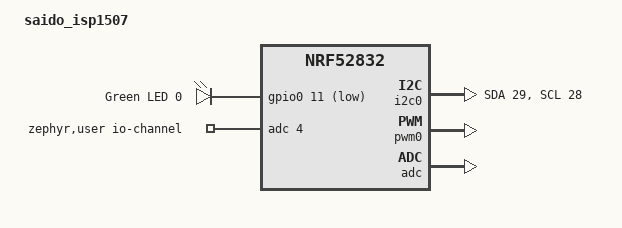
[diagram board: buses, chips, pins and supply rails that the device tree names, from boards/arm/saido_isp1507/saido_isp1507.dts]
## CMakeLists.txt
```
# SPDX-License-Identifier: Apache-2.0

cmake_minimum_required(VERSION 3.20.0)
find_package(Zephyr REQUIRED HINTS $ENV{ZEPHYR_BASE})
project(sensor)

target_sources(app
    PRIVATE
        src/main.c src/sht3x.c src/qmp6988.c src/sgp30.c
        src/battery.c
        src/app_bt.c
    )
```

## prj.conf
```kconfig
CONFIG_GPIO=y
CONFIG_LOG=y
CONFIG_LOG_DEFAULT_LEVEL=4
CONFIG_RTT_CONSOLE=y
# CONFIG_CBPRINTF_FP_SUPPORT=y
CONFIG_I2C=y
CONFIG_ADC=y
CONFIG_NEWLIB_LIBC=y

CONFIG_BT=y
CONFIG_BT_PERIPHERAL=y
CONFIG_BT_DEVICE_NAME="nrf52_sensor"
```

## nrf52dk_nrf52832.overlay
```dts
// To get started, press Ctrl+Space to bring up the completion menu and view the available nodes.
// For more help, browse the DeviceTree documentation at https: //docs.zephyrproject.org/latest/guides/dts/index.html
/ {
    model = "saido isp1507";
    compatible = "nordic,nrf52-dk-nrf52832";

    chosen {
        zephyr,console = &uart0;
        zephyr,shell-uart = &uart0;
        zephyr,uart-mcumgr = &uart0;
        zephyr,bt-mon-uart = &uart0;
        zephyr,bt-c2h-uart = &uart0;
        zephyr,sram = &sram0;
        zephyr,flash = &flash0;
        zephyr,code-partition = &slot0_partition;
    };

    leds {
        compatible = "gpio-leds";
        led0: led_0 {
            gpios = <&gpio0 11 GPIO_ACTIVE_LOW>;
            label = "on board led";
        };
        led1: led_1 {
            status = "disabled";
        };
        led2: led_2 {
            status = "disabled";
        };
        led3: led_3 {
            status = "disabled";
        };
    };

    pwmleds {
        compatible = "pwm-leds";
        pwm_led0: pwm_led_0 {
            pwms = <&pwm0 11>;
        };
    };

    buttons {
        status = "disabled";
    };

    arduino_header: connector {
        status = "disabled";
    };

    arduino_adc: analog-connector {
        status = "disabled";
    };

    /* These aliases are provided for compatibility with samples */
    aliases {
        led0 = &led0;
        led1 = &led1;
        led2 = &led2;
        led3 = &led3;
        pwm-led0 = &pwm_led0;
        sw0 = &button0;
        sw1 = &button1;
        sw2 = &button2;
        sw3 = &button3;
        bootloader-led0 = &led0;
    };
};

&adc {
    status = "disabled";
};

&gpiote {
    status = "okay";
};

&gpio0 {
    status = "okay";
};

arduino_serial: &uart0 {
    status = "disabled";
};

arduino_i2c: &i2c0 {
    compatible = "nordic,nrf-twi";
    status = "okay";
    sda-pin = <29>;
    scl-pin = <28>;
};

&i2c1 {
    compatible = "nordic,nrf-twi";
    /* Cannot be used together with spi1. */
    status = "disabled";
};

&pwm0 {
    status = "okay";
    ch0-pin = <17>;
    ch0-inverted;
};

&spi0 {
    compatible = "nordic,nrf-spi";
    /* Cannot be used together with i2c0. */
    status = "disabled";
};

&spi1 {
    compatible = "nordic,nrf-spi";
    status = "disabled";
};

arduino_spi: &spi2 {
    compatible = "nordic,nrf-spi";
    status = "disabled";
};

&flash0 {

    partitions {
        compatible = "fixed-partitions";
        #address-cells = <1>;
        #size-cells = <1>;

        boot_partition: partition@0 {
            label = "mcuboot";
            reg = <0x00000000 0xc000>;
        };
        slot0_partition: partition@c000 {
            label = "image-0";
            reg = <0x0000C000 0x32000>;
        };
        slot1_partition: partition@3e000 {
            label = "image-1";
            reg = <0x0003E000 0x32000>;
        };
        scratch_partition: partition@70000 {
            label = "image-scratch";
            reg = <0x00070000 0xa000>;
        };
        storage_partition: partition@7a000 {
            label = "storage";
            reg = <0x0007a000 0x00006000>;
        };
    };
};
```

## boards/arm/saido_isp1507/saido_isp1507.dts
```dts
// Copyright (c) 2022 Nordic Semiconductor ASA
// SPDX-License-Identifier: Apache-2.0

/dts-v1/;
#include <nordic/nrf52832_ciaa.dtsi>

/ {
	model = "saido_isp1507";
	compatible = "h-saido,saido-isp1507";

	chosen {
		zephyr,sram = &sram0;
		zephyr,flash = &flash0;
		zephyr,code-partition = &slot0_partition;
	};

	leds {
		compatible = "gpio-leds";
		led0: led_0 {
			gpios = <&gpio0 11 GPIO_ACTIVE_LOW>;
			label = "Green LED 0";
		};
	};

	// FIXME: Error on NCS v2.0.0 (This can build with NCS v1.9.1 or lower)
	// pwmleds {
	// 	compatible = "pwm-leds";
	// 	pwm_led0: pwm_led_0 {
	// 		pwms = <&pwm0 11>;
	// 	};
	// };


	/* These aliases are provided for compatibility with samples */
	aliases {
		led0 = &led0;
		// pwm-led0 = &pwm_led0;
		bootloader-led0 = &led0;
	};

	zephyr,user {
		io-channels = <&adc 4>;
	 };
};

&gpio0 {
	status = "okay";
};

i2c: &i2c0 {
	compatible = "nordic,nrf-twi";
	status = "okay";
	sda-pin = <29>;
	scl-pin = <28>;
};

&pwm0 {
	status = "okay";
	ch0-pin = <11>;
	ch0-inverted;
};

&adc {
	status = "okay";
};

&flash0 {
	partitions {
		compatible = "fixed-partitions";
		#address-cells = <1>;
		#size-cells = <1>;

		boot_partition: partition@0 {
			label = "mcuboot";
			reg = <0x0 0xc000>;
		};
		slot0_partition: partition@c000 {
			label = "image-0";
			reg = <0xc000 0x32000>;
		};
		slot1_partition: partition@3e000 {
			label = "image-1";
			reg = <0x3e000 0x32000>;
		};
		scratch_partition: partition@70000 {
			label = "image-scratch";
			reg = <0x70000 0xa000>;
		};
		storage_partition: partition@7a000 {
			label = "storage";
			reg = <0x7a000 0x6000>;
		};
	};
};
```

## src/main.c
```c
/*
 * Copyright (c) 2016 Intel Corporation
 *
 * SPDX-License-Identifier: Apache-2.0
 */

#include <stdio.h>

#include <device.h>
#include <devicetree.h>
#include <drivers/gpio.h>
#include <drivers/i2c.h>
#include <kernel.h>
#include <zephyr.h>

#include <logging/log.h>
LOG_MODULE_REGISTER(sensor);

#include "battery.h"
#include "qmp6988.h"
#include "sgp30.h"
#include "sht3x.h"

#include "app_bt.h"

/* 1000 msec = 1 sec */
#define SLEEP_TIME_MS 5000

// NOTE: SGP30 is very high comsumption (about 50 mA), so disable it
#define CONFIG_SGP30

struct sensors {
    const struct device *i2c_dev;
    sht3x_sensor_t      *sht3x;
    qmp6988_sensor_t    *qmp6988;
#ifdef CONFIG_SGP30
    sgp30_sensor_t *sgp30;
#endif
    float temperature;
    float humidity;
    float pressure;
    float temperature_p;
};

typedef struct {
    int   battery_mV;
    float temperature;
    float humidity;
    float pressure;
#ifdef CONFIG_SGP30
    uint16_t co2;
    uint16_t tvoc;
#endif
} send_data_t;

static struct sensors env_sensors = {
    .i2c_dev = DEVICE_DT_GET(DT_NODELABEL(i2c0)),
    .sht3x   = NULL,
    .qmp6988 = NULL,
#ifdef CONFIG_SGP30
    .sgp30 = NULL,
#endif
};

static struct gpio_dt_spec led0_spec = GPIO_DT_SPEC_GET(DT_NODELABEL(led0), gpios);

static send_data_t send_data = {
    .battery_mV  = 0,
    .temperature = 0,
    .humidity    = 0,
    .pressure    = 0,
#ifdef CONFIG_SGP30
    .co2  = 0,
    .tvoc = 0,
#endif
};

static bool init_i2c_sensors(struct sensors *env_sensors);
static void get_i2c_sensors_values(struct sensors *env_sensors);
static void app_work_handler(struct k_work *work);
static void app_timer_handler(struct k_timer *dummy);

K_WORK_DEFINE(app_work, app_work_handler);
K_TIMER_DEFINE(app_timer, app_timer_handler, NULL);

static void app_work_handler(struct k_work *work)
{
    gpio_pin_set_dt(&led0_spec, 0);

    battery_measure_enable(true);
    int batt_mV = battery_sample();
    if (batt_mV < 0) {
        LOG_WRN("Failed to read battery voltage: %d\n", batt_mV);
    } else {
        send_data.battery_mV = batt_mV;
    }
    battery_measure_enable(false);

    get_i2c_sensors_values(&env_sensors);
#ifdef CONFIG_SGP30
    LOG_INF(
        "%d C %d %% %4d hPa(t=%2d) %d ppm CO2 %d ppm TVOC %d mV", (int)env_sensors.temperature,
        (int)env_sensors.humidity, (int)env_sensors.pressure, (int)env_sensors.temperature_p, env_sensors.sgp30->CO2,
        env_sensors.sgp30->TVOC, batt_mV
    );
#else
    LOG_INF(
        "%d C %d %% %4d hPa(t=%2d) %d mV", (int)env_sensors.temperature, (int)env_sensors.humidity,
        (int)env_sensors.pressure, (int)env_sensors.temperature_p, batt_mV
    );
#endif

    send_data.temperature = env_sensors.temperature;
    send_data.humidity    = env_sensors.humidity;
    send_data.pressure    = env_sensors.pressure;
#ifdef CONFIG_SGP30
    send_data.co2 = env_sensors.sgp30->CO2;
    send_data.tvoc = env_sensors.sgp30->TVOC;
#endif
    bt_app_send_data(&send_data, sizeof(send_data_t));

    gpio_pin_set_dt(&led0_spec, 1);
}

static void app_timer_handler(struct k_timer *dummy)
{
    k_work_submit(&app_work);
}

static void connected(struct bt_conn *conn, uint8_t err)
{
    if (err) {
        printk("Connection failed (err %u)\n", err);
        return;
    }

    printk("Connected\n");
}

static void disconnected(struct bt_conn *conn, uint8_t reason)
{
    printk("Disconnected (reason %u)\n", reason);
}

BT_CONN_CB_DEFINE(conn_callbacks) = {
    .connected    = connected,
    .disconnected = disconnected,
};

static int app_bt_cb(void *data)
{
    // Note: The maximum data size is defined by APP_BT_MAX_ATTR_LEN.
    if (APP_BT_MAX_ATTR_LEN < sizeof(send_data_t)) {
        LOG_ERR("app_bt_cb(): Too large data size");
        return -EINVAL;
    }
    memcpy(data, &send_data, sizeof(send_data_t));
    return sizeof(send_data_t);
}

static struct bt_app_cb app_callbacks = {
    .app_bt_cb = app_bt_cb,
};

static bool init_i2c_sensors(struct sensors *env_sensors)
{
    env_sensors->sht3x = sht3x_init_sensor(env_sensors->i2c_dev, SHT3x_ADDR_1);
    if (env_sensors->sht3x == NULL) {
        LOG_ERR("Cannot init sht3x sensor");
        return false;
    }

    // Wait until first measurement is ready (constant time of at least 30 ms
    // or the duration returned from *sht3x_get_measurement_duration*).
    k_msleep(sht3x_get_measurement_duration(sht3x_high));

    env_sensors->qmp6988 = qmp6988_init_sensor(env_sensors->i2c_dev, QMP6988_SLAVE_ADDRESS_L);
    if (env_sensors->qmp6988 == NULL) {
        LOG_ERR("Cannot init qmp6988 sensor");
        return false;
    }

#ifdef CONFIG_SGP30
    env_sensors->sgp30 = sgp30_init_sensor(env_sensors->i2c_dev, SGP30_I2C_DEFAULT_ADDRESS);
    if (env_sensors->sgp30 == NULL) {
        LOG_ERR("Cannot init sgp30 sensor");
        return false;
    }
    sgp30_initAirQuality(env_sensors->sgp30);
    k_msleep(INIT_AIR_QUALITY_DURATION_MS);
#endif

    return true;
}

static void get_i2c_sensors_values(struct sensors *env_sensors)
{
    int ret;
    ret = sht3x_measure(env_sensors->sht3x, &env_sensors->temperature, &env_sensors->humidity);
    qmp6988_calcPressure(env_sensors->qmp6988, &env_sensors->pressure, &env_sensors->temperature_p);
#ifdef CONFIG_SGP30
    sgp30_measureAirQuality(env_sensors->sgp30);
    if (ret) {
        sgp30_setCompensation(env_sensors->sgp30, env_sensors->humidity, env_sensors->temperature);
    }
#endif
}

void main(void)
{
    LOG_MODULE_DECLARE(sensor);
    int ret;

    ret = gpio_pin_configure_dt(&led0_spec, GPIO_OUTPUT_ACTIVE);
    if (ret < 0) {
        LOG_ERR("Cannot configure LED pin [%d]", ret);
        return;
    }

    ret = init_i2c_sensors(&env_sensors);
    if (!ret) {
        LOG_ERR("Cannot init i2c sensors [%d]", ret);
        return;
    }

    ret = bt_app_init(&app_callbacks);
    if (ret) {
        LOG_ERR("Failed to init bt [%d]", ret);
        return;
    }

    ret = bt_app_advertise_start();
    if (ret) {
        LOG_ERR("Failed to start advertising [%d]", ret);
        return;
    }

    /* start periodic timer that expires once every 10 seconds */
    k_timer_start(&app_timer, K_SECONDS(1), K_MSEC(SLEEP_TIME_MS));

    // do nothing
}
```

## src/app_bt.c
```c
#include <errno.h>
#include <stddef.h>
#include <string.h>
#include <sys/byteorder.h>
#include <sys/printk.h>
#include <zephyr.h>
#include <zephyr/types.h>

#include <bluetooth/bluetooth.h>
#include <bluetooth/conn.h>
#include <bluetooth/gatt.h>
#include <bluetooth/hci.h>
#include <bluetooth/uuid.h>

#include <logging/log.h>

#include "app_bt.h"

LOG_MODULE_REGISTER(app_bt, CONFIG_LOG_DEFAULT_LEVEL);

static bool             notify_enabled;
static char             char_value[APP_BT_MAX_ATTR_LEN];
static struct bt_app_cb app_cb;

static void app_ccc_cfg_changed(const struct bt_gatt_attr *attr, uint16_t value)
{
    notify_enabled = (value == BT_GATT_CCC_NOTIFY);
}

static ssize_t read_function(
    struct bt_conn *conn, const struct bt_gatt_attr *attr, void *buf, uint16_t len, uint16_t offset
)
{
    LOG_DBG("Attribute read, handle: %u, conn: %p", attr->handle, (void *)conn);

    if (app_cb.app_bt_cb) {
        int data_len = app_cb.app_bt_cb(attr->user_data);
        if (data_len < 0) {
            return data_len;
        }

        return bt_gatt_attr_read(conn, attr, buf, len, offset, attr->user_data, data_len);
    }

    return 0;
}

BT_GATT_SERVICE_DEFINE(
    app_svc, BT_GATT_PRIMARY_SERVICE(APP_BT_UUID_BASE),
    BT_GATT_CHARACTERISTIC(
        APP_BT_UUID_CHAR, BT_GATT_CHRC_READ | BT_GATT_CHRC_NOTIFY, BT_GATT_PERM_READ, read_function, NULL, char_value
    ),
    BT_GATT_CCC(app_ccc_cfg_changed, BT_GATT_PERM_READ | BT_GATT_PERM_WRITE),
);

int bt_app_init(struct bt_app_cb *callbacks)
{
    if (callbacks) {
        app_cb.app_bt_cb = callbacks->app_bt_cb;
    }

    return bt_enable(NULL);
}

int bt_app_send_data(void *data, int len)
{
    if (!notify_enabled) {
        return -EACCES;
    }

    return bt_gatt_notify(NULL, &app_svc.attrs[2], data, (uint16_t)len);
}

int bt_app_advertise_start(void)
{
    const struct bt_data ad[] = {
        BT_DATA_BYTES(BT_DATA_FLAGS, (BT_LE_AD_GENERAL | BT_LE_AD_NO_BREDR)),
        BT_DATA(BT_DATA_NAME_COMPLETE, DEVICE_NAME, DEVICE_NAME_LEN),
    };

    const struct bt_data sd[] = {
        BT_DATA_BYTES(BT_DATA_UUID128_ALL, APP_BT_UUID_BASE_VAL),
    };

    return bt_le_adv_start(BT_LE_ADV_CONN, ad, ARRAY_SIZE(ad), sd, ARRAY_SIZE(sd));
}
```

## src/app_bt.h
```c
#ifndef BT_APP_H_
#define BT_APP_H_

#include <bluetooth/bluetooth.h>
#include <bluetooth/conn.h>
#include <bluetooth/gatt.h>
#include <bluetooth/hci.h>
#include <bluetooth/uuid.h>

#define DEVICE_NAME     CONFIG_BT_DEVICE_NAME
#define DEVICE_NAME_LEN (sizeof(DEVICE_NAME) - 1)
// random number
#define APP_BT_UUID_BASE_VAL BT_UUID_128_ENCODE(0xc7839aa8, 0x1903, 0x40b5, 0xa8f0, 0x426e09ffb390)
#define APP_BT_UUID_CHAR_VAL BT_UUID_128_ENCODE(0xc7839aa9, 0x1903, 0x40b5, 0xa8f0, 0x426e09ffb390)

#define APP_BT_UUID_BASE BT_UUID_DECLARE_128(APP_BT_UUID_BASE_VAL)
#define APP_BT_UUID_CHAR BT_UUID_DECLARE_128(APP_BT_UUID_CHAR_VAL)

#define APP_BT_MAX_ATTR_LEN 64

typedef int (*app_bt_cb_t)(void *data);

struct bt_app_cb {
    app_bt_cb_t app_bt_cb;
};

/** @brief Initialize the app_bt Service.
 *
 * @param[in] callbacks Struct containing pointers to callback functions
 *			used by the service. This pointer can be NULL
 *			if no callback functions are defined.
 *
 * @retval 0 If the operation was successful.
 *           Otherwise, a (negative) error code is returned.
 */
int bt_app_init(struct bt_app_cb *callbacks);

/** @brief Send data (notify).
 *
 * If the notify is not enabled, the data will be discarded.
 *
 * @param[in] data notify data. Able to input any data.
 * @param[in] len length of notify data.
 *
 * @retval 0 If the operation was successful.
 *           Otherwise, a (negative) error code is returned.
 */
int bt_app_send_data(void *data, int len);

/** @brief Start advertising.
 *
 * @retval 0 If the operation was successful.
 *           Otherwise, a (negative) error code is returned.
 */
int bt_app_advertise_start(void);

#endif
```

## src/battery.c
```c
/*
 * Copyright (c) 2018-2019 Peter Bigot Consulting, LLC
 * Copyright (c) 2019-2020 Nordic Semiconductor ASA
 *
 * SPDX-License-Identifier: Apache-2.0
 */

#include <math.h>
#include <stdio.h>
#include <stdlib.h>

#include <drivers/adc.h>
#include <drivers/gpio.h>
#include <drivers/sensor.h>
#include <init.h>
#include <logging/log.h>
#include <zephyr.h>

#include "battery.h"

LOG_MODULE_REGISTER(BATTERY, CONFIG_ADC_LOG_LEVEL);

#define VBATT       DT_PATH(vbatt)
#define ZEPHYR_USER DT_PATH(zephyr_user)

#ifdef CONFIG_BOARD_THINGY52_NRF52832
/* This board uses a divider that reduces max voltage to
 * reference voltage (600 mV).
 */
#define BATTERY_ADC_GAIN ADC_GAIN_1
#else
/* Other boards may use dividers that only reduce battery voltage to
 * the maximum supported by the hardware (3.6 V)
 */
#define BATTERY_ADC_GAIN ADC_GAIN_1_6
#endif

struct io_channel_config {
    uint8_t channel;
};

struct gpio_channel_config {
    const char *label;
    uint8_t     pin;
    uint8_t     flags;
};

struct divider_config {
    struct io_channel_config   io_channel;
    struct gpio_channel_config power_gpios;
    /* output_ohm is used as a flag value: if it is nonzero then
     * the battery is measured through a voltage divider;
     * otherwise it is assumed to be directly connected to Vdd.
     */
    uint32_t output_ohm;
    uint32_t full_ohm;
};

static const struct divider_config divider_config = {
#if DT_NODE_HAS_STATUS(VBATT, okay)
    .io_channel =
        {
            DT_IO_CHANNELS_INPUT(VBATT),
        },
#if DT_NODE_HAS_PROP(VBATT, power_gpios)
    .power_gpios =
        {
            DT_GPIO_LABEL(VBATT, power_gpios),
            DT_GPIO_PIN(VBATT, power_gpios),
            DT_GPIO_FLAGS(VBATT, power_gpios),
        },
#endif
    .output_ohm = DT_PROP(VBATT, output_ohms),
    .full_ohm   = DT_PROP(VBATT, full_ohms),
#else  /* /vbatt exists */
    .io_channel =
        {
            DT_IO_CHANNELS_INPUT(ZEPHYR_USER),
        },
#endif /* /vbatt exists */
};

struct divider_data {
    const struct device   *adc;
    const struct device   *gpio;
    struct adc_channel_cfg adc_cfg;
    struct adc_sequence    adc_seq;
    int16_t                raw;
};
static struct divider_data divider_data = {
#if DT_NODE_HAS_STATUS(VBATT, okay)
    .adc = DEVICE_DT_GET(DT_IO_CHANNELS_CTLR(VBATT)),
#else
    .adc = DEVICE_DT_GET(DT_IO_CHANNELS_CTLR(ZEPHYR_USER)),
#endif
};

static int divider_setup(void)
{
    const struct divider_config      *cfg  = &divider_config;
    const struct io_channel_config   *iocp = &cfg->io_channel;
    const struct gpio_channel_config *gcp  = &cfg->power_gpios;
    struct divider_data              *ddp  = &divider_data;
    struct adc_sequence              *asp  = &ddp->adc_seq;
    struct adc_channel_cfg           *accp = &ddp->adc_cfg;
    int                               rc;

    if (!device_is_ready(ddp->adc)) {
        LOG_ERR("ADC device is not ready %s", ddp->adc->name);
        return -ENOENT;
    }

    if (gcp->label) {
        ddp->gpio = device_get_binding(gcp->label);
        if (ddp->gpio == NULL) {
            LOG_ERR("Failed to get GPIO %s", gcp->label);
            return -ENOENT;
        }
        rc = gpio_pin_configure(ddp->gpio, gcp->pin, GPIO_OUTPUT_INACTIVE | gcp->flags);
        if (rc != 0) {
            LOG_ERR("Failed to control feed %s.%u: %d", gcp->label, gcp->pin, rc);
            return rc;
        }
    }

    *asp = (struct adc_sequence){
        .channels     = BIT(0),
        .buffer       = &ddp->raw,
        .buffer_size  = sizeof(ddp->raw),
        .oversampling = 4,
        .calibrate    = true,
    };

#ifdef CONFIG_ADC_NRFX_SAADC
    *accp = (struct adc_channel_cfg){
        .gain             = BATTERY_ADC_GAIN,
        .reference        = ADC_REF_INTERNAL,
        .acquisition_time = ADC_ACQ_TIME(ADC_ACQ_TIME_MICROSECONDS, 40),
    };

    if (cfg->output_ohm != 0) {
        accp->input_positive = SAADC_CH_PSELP_PSELP_AnalogInput0 + iocp->channel;
    } else {
        accp->input_positive = SAADC_CH_PSELP_PSELP_VDD;
    }

    asp->resolution = 14;
#else /* CONFIG_ADC_var */
#error Unsupported ADC
#endif /* CONFIG_ADC_var */

    rc = adc_channel_setup(ddp->adc, accp);
    // LOG_INF("Setup AIN%u got %d", iocp->channel, rc);

    return rc;
}

static bool battery_ok;

static int battery_setup(const struct device *arg)
{
    int rc = divider_setup();

    battery_ok = (rc == 0);
    // LOG_INF("Battery setup: %d %d", rc, battery_ok);
    return rc;
}

SYS_INIT(battery_setup, APPLICATION, CONFIG_APPLICATION_INIT_PRIORITY);

int battery_measure_enable(bool enable)
{
    int rc = -ENOENT;

    if (battery_ok) {
        const struct divider_data        *ddp = &divider_data;
        const struct gpio_channel_config *gcp = &divider_config.power_gpios;

        rc = 0;
        if (ddp->gpio) {
            rc = gpio_pin_set(ddp->gpio, gcp->pin, enable);
        }
    }
    return rc;
}

int battery_sample(void)
{
    int rc = -ENOENT;

    if (battery_ok) {
        struct divider_data         *ddp = &divider_data;
        const struct divider_config *dcp = &divider_config;
        struct adc_sequence         *sp  = &ddp->adc_seq;

        rc            = adc_read(ddp->adc, sp);
        sp->calibrate = false;
        if (rc == 0) {
            int32_t val = ddp->raw;

            adc_raw_to_millivolts(adc_ref_internal(ddp->adc), ddp->adc_cfg.gain, sp->resolution, &val);

            if (dcp->output_ohm != 0) {
                rc = val * (uint64_t)dcp->full_ohm / dcp->output_ohm;
                // LOG_INF("raw %u ~ %u mV => %d mV\n",
                // 	ddp->raw, val, rc);
            } else {
                rc = val;
                // LOG_INF("raw %u ~ %u mV\n", ddp->raw, val);
            }
        }
    }

    return rc;
}

unsigned int battery_level_pptt(unsigned int batt_mV, const struct battery_level_point *curve)
{
    const struct battery_level_point *pb = curve;

    if (batt_mV >= pb->lvl_mV) {
        /* Measured voltage above highest point, cap at maximum. */
        return pb->lvl_pptt;
    }
    /* Go down to the last point at or below the measured voltage. */
    while ((pb->lvl_pptt > 0) && (batt_mV < pb->lvl_mV)) {
        ++pb;
    }
    if (batt_mV < pb->lvl_mV) {
        /* Below lowest point, cap at minimum */
        return pb->lvl_pptt;
    }

    /* Linear interpolation between below and above points. */
    const struct battery_level_point *pa = pb - 1;

    return pb->lvl_pptt + ((pa->lvl_pptt - pb->lvl_pptt) * (batt_mV - pb->lvl_mV) / (pa->lvl_mV - pb->lvl_mV));
}
```

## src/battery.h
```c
/*
 * Copyright (c) 2018-2019 Peter Bigot Consulting, LLC
 *
 * SPDX-License-Identifier: Apache-2.0
 */

#ifndef APPLICATION_BATTERY_H_
#define APPLICATION_BATTERY_H_

/** Enable or disable measurement of the battery voltage.
 *
 * @param enable true to enable, false to disable
 *
 * @return zero on success, or a negative error code.
 */
int battery_measure_enable(bool enable);

/** Measure the battery voltage.
 *
 * @return the battery voltage in millivolts, or a negative error
 * code.
 */
int battery_sample(void);

/** A point in a battery discharge curve sequence.
 *
 * A discharge curve is defined as a sequence of these points, where
 * the first point has #lvl_pptt set to 10000 and the last point has
 * #lvl_pptt set to zero.  Both #lvl_pptt and #lvl_mV should be
 * monotonic decreasing within the sequence.
 */
struct battery_level_point {
    /** Remaining life at #lvl_mV. */
    uint16_t lvl_pptt;

    /** Battery voltage at #lvl_pptt remaining life. */
    uint16_t lvl_mV;
};

/** Calculate the estimated battery level based on a measured voltage.
 *
 * @param batt_mV a measured battery voltage level.
 *
 * @param curve the discharge curve for the type of battery installed
 * on the system.
 *
 * @return the estimated remaining capacity in parts per ten
 * thousand.
 */
unsigned int battery_level_pptt(unsigned int batt_mV, const struct battery_level_point *curve);

#endif /* APPLICATION_BATTERY_H_ */
```

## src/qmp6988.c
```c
// https://github.com/m5stack/UNIT_ENV
//
// MIT License
//
// Copyright (c) 2021 M5Stack
//
// Permission is hereby granted, free of charge, to any person obtaining a copy
// of this software and associated documentation files (the "Software"), to deal
// in the Software without restriction, including without limitation the rights
// to use, copy, modify, merge, publish, distribute, sublicense, and/or sell
// copies of the Software, and to permit persons to whom the Software is
// furnished to do so, subject to the following conditions:
//
// The above copyright notice and this permission notice shall be included in all
// copies or substantial portions of the Software.
//
// THE SOFTWARE IS PROVIDED "AS IS", WITHOUT WARRANTY OF ANY KIND, EXPRESS OR
// IMPLIED, INCLUDING BUT NOT LIMITED TO THE WARRANTIES OF MERCHANTABILITY,
// FITNESS FOR A PARTICULAR PURPOSE AND NONINFRINGEMENT. IN NO EVENT SHALL THE
// AUTHORS OR COPYRIGHT HOLDERS BE LIABLE FOR ANY CLAIM, DAMAGES OR OTHER
// LIABILITY, WHETHER IN AN ACTION OF CONTRACT, TORT OR OTHERWISE, ARISING FROM,
// OUT OF OR IN CONNECTION WITH THE SOFTWARE OR THE USE OR OTHER DEALINGS IN THE
// SOFTWARE.

#include <stdlib.h>
#include <string.h>

#include <drivers/i2c.h>

#include "qmp6988.h"

static uint8_t qmp6988_deviceCheck(qmp6988_sensor_t *dev);
static bool    qmp6988_softwareReset(qmp6988_sensor_t *dev);
static int     qmp6988_getCalibrationData(qmp6988_sensor_t *dev);
static int16_t qmp6988_convTx02e(qmp6988_ik_data_t *ik, int32_t dt);
static int32_t qmp6988_getPressure02e(qmp6988_ik_data_t *ik, int32_t dp, int16_t tx);
static bool    qmp6988_read_data(qmp6988_sensor_t *dev, uint8_t reg_addr, uint8_t *data, uint32_t len);
static bool    qmp6988_write_reg(qmp6988_sensor_t *dev, uint8_t reg_addr, uint8_t data);

static qmp6988_sensor_t g_dev; // mallocできないのでここに宣言

qmp6988_sensor_t *qmp6988_init_sensor(const struct device *i2c_dev, uint8_t addr)
{
    qmp6988_sensor_t *dev;

    // if ((dev = malloc(sizeof(qmp6988_sensor_t))) == NULL)
    //     return NULL;
    dev = &g_dev;

    // inititalize sensor data structure
    dev->bus  = i2c_dev;
    dev->addr = addr;

    uint8_t ret = qmp6988_deviceCheck(dev);
    if (ret == 0) {
        // free(dev);
        return NULL;
    }

    qmp6988_softwareReset(dev);
    qmp6988_getCalibrationData(dev);
    qmp6988_setpPowermode(dev, QMP6988_NORMAL_MODE);
    qmp6988_setFilter(dev, QMP6988_FILTERCOEFF_4);
    qmp6988_setOversamplingP(dev, QMP6988_OVERSAMPLING_8X);
    qmp6988_setOversamplingT(dev, QMP6988_OVERSAMPLING_1X);

    return dev;
}

bool qmp6988_calcPressure(qmp6988_sensor_t *dev, float *pressure, float *temperature)
{
    uint8_t  err = 0;
    uint32_t P_read, T_read;
    int32_t  P_raw, T_raw;
    uint8_t  a_data_tr[6] = {0};
    int32_t  T_int, P_int;

    // press
    err = qmp6988_read_data(dev, QMP6988_PRESSURE_MSB_REG, a_data_tr, 6);
    if (!err) {
        return false;
    }
    P_read = (uint32_t)((((uint32_t)(a_data_tr[0])) << 16) | (((uint16_t)(a_data_tr[1])) << 8) | (a_data_tr[2]));
    P_raw  = (int32_t)(P_read - SUBTRACTOR);

    T_read = (uint32_t)((((uint32_t)(a_data_tr[3])) << 16) | (((uint16_t)(a_data_tr[4])) << 8) | (a_data_tr[5]));
    T_raw  = (int32_t)(T_read - SUBTRACTOR);

    T_int        = qmp6988_convTx02e(&(dev->ik), T_raw);
    P_int        = qmp6988_getPressure02e(&(dev->ik), P_raw, T_int);
    *temperature = (float)T_int / 256.0f;
    *pressure    = (float)P_int / 1600.0f;

    return true;
}

uint8_t qmp6988_deviceCheck(qmp6988_sensor_t *dev)
{
    uint8_t ret = 0;
    uint8_t id;

    ret = qmp6988_read_data(dev, QMP6988_CHIP_ID_REG, &(id), 1);
    if (!ret) {
        return 0;
    }

    if (id != QMP6988_CHIP_ID) {
        return 0;
    }

    return 1;
}

bool qmp6988_softwareReset(qmp6988_sensor_t *dev)
{
    uint8_t ret;

    ret = qmp6988_write_reg(dev, QMP6988_RESET_REG, 0);
    if (!ret) {
        return false;
    }

    k_msleep(20);

    ret = qmp6988_write_reg(dev, QMP6988_RESET_REG, 0);
    if (!ret) {
        return false;
    }

    return true;
}

int qmp6988_getCalibrationData(qmp6988_sensor_t *dev)
{
    uint8_t a_data_tr[QMP6988_CALIBRATION_DATA_LENGTH] = {0};

    int ret = qmp6988_read_data(dev, QMP6988_CALIBRATION_DATA_START, a_data_tr, QMP6988_CALIBRATION_DATA_LENGTH);
    if (!ret) {
        return 0;
    }

    dev->cali.COE_a0 = (int32_t)(((a_data_tr[18] << 12) | (a_data_tr[19] << 4) | (a_data_tr[24] & 0x0f)) << 12);
    dev->cali.COE_a0 = dev->cali.COE_a0 >> 12;

    dev->cali.COE_a1 = (int16_t)(((a_data_tr[20]) << 8) | a_data_tr[21]);
    dev->cali.COE_a2 = (int16_t)(((a_data_tr[22]) << 8) | a_data_tr[23]);

    dev->cali.COE_b00 = (int32_t)(((a_data_tr[0] << 12) | (a_data_tr[1] << 4) | ((a_data_tr[24] & 0xf0) >> 4)) << 12);
    dev->cali.COE_b00 = dev->cali.COE_b00 >> 12;

    dev->cali.COE_bt1 = (int16_t)(((a_data_tr[2]) << 8) | a_data_tr[3]);
    dev->cali.COE_bt2 = (int16_t)(((a_data_tr[4]) << 8) | a_data_tr[5]);
    dev->cali.COE_bp1 = (int16_t)(((a_data_tr[6]) << 8) | a_data_tr[7]);
    dev->cali.COE_b11 = (int16_t)(((a_data_tr[8]) << 8) | a_data_tr[9]);
    dev->cali.COE_bp2 = (int16_t)(((a_data_tr[10]) << 8) | a_data_tr[11]);
    dev->cali.COE_b12 = (int16_t)(((a_data_tr[12]) << 8) | a_data_tr[13]);
    dev->cali.COE_b21 = (int16_t)(((a_data_tr[14]) << 8) | a_data_tr[15]);
    dev->cali.COE_bp3 = (int16_t)(((a_data_tr[16]) << 8) | a_data_tr[17]);

    dev->ik.a0  = dev->cali.COE_a0;  // 20Q4
    dev->ik.b00 = dev->cali.COE_b00; // 20Q4

    dev->ik.a1 = 3608L * (int32_t)dev->cali.COE_a1 - 1731677965L; // 31Q23
    dev->ik.a2 = 16889L * (int32_t)dev->cali.COE_a2 - 87619360L;  // 30Q47

    dev->ik.bt1 = 2982L * (int64_t)dev->cali.COE_bt1 + 107370906L;   // 28Q15
    dev->ik.bt2 = 329854L * (int64_t)dev->cali.COE_bt2 + 108083093L; // 34Q38
    dev->ik.bp1 = 19923L * (int64_t)dev->cali.COE_bp1 + 1133836764L; // 31Q20
    dev->ik.b11 = 2406L * (int64_t)dev->cali.COE_b11 + 118215883L;   // 28Q34
    dev->ik.bp2 = 3079L * (int64_t)dev->cali.COE_bp2 - 181579595L;   // 29Q43
    dev->ik.b12 = 6846L * (int64_t)dev->cali.COE_b12 + 85590281L;    // 29Q53
    dev->ik.b21 = 13836L * (int64_t)dev->cali.COE_b21 + 79333336L;   // 29Q60
    dev->ik.bp3 = 2915L * (int64_t)dev->cali.COE_bp3 + 157155561L;   // 28Q65

    return 1;
}

int16_t qmp6988_convTx02e(qmp6988_ik_data_t *ik, int32_t dt)
{
    int16_t ret;
    int64_t wk1, wk2;

    // wk1: 60Q4 // bit size
    wk1 = ((int64_t)ik->a1 * (int64_t)dt);       // 31Q23+24-1=54 (54Q23)
    wk2 = ((int64_t)ik->a2 * (int64_t)dt) >> 14; // 30Q47+24-1=53 (39Q33)
    wk2 = (wk2 * (int64_t)dt) >> 10;             // 39Q33+24-1=62 (52Q23)
    wk2 = ((wk1 + wk2) / 32767) >> 19;           // 54,52->55Q23 (20Q04)
    ret = (int16_t)((ik->a0 + wk2) >> 4);        // 21Q4 -> 17Q0
    return ret;
}

int32_t qmp6988_getPressure02e(qmp6988_ik_data_t *ik, int32_t dp, int16_t tx)
{
    int32_t ret;
    int64_t wk1, wk2, wk3;

    // wk1 = 48Q16 // bit size
    wk1 = ((int64_t)ik->bt1 * (int64_t)tx);       // 28Q15+16-1=43 (43Q15)
    wk2 = ((int64_t)ik->bp1 * (int64_t)dp) >> 5;  // 31Q20+24-1=54 (49Q15)
    wk1 += wk2;                                   // 43,49->50Q15
    wk2 = ((int64_t)ik->bt2 * (int64_t)tx) >> 1;  // 34Q38+16-1=49 (48Q37)
    wk2 = (wk2 * (int64_t)tx) >> 8;               // 48Q37+16-1=63 (55Q29)
    wk3 = wk2;                                    // 55Q29
    wk2 = ((int64_t)ik->b11 * (int64_t)tx) >> 4;  // 28Q34+16-1=43 (39Q30)
    wk2 = (wk2 * (int64_t)dp) >> 1;               // 39Q30+24-1=62 (61Q29)
    wk3 += wk2;                                   // 55,61->62Q29
    wk2 = ((int64_t)ik->bp2 * (int64_t)dp) >> 13; // 29Q43+24-1=52 (39Q30)
    wk2 = (wk2 * (int64_t)dp) >> 1;               // 39Q30+24-1=62 (61Q29)
    wk3 += wk2;                                   // 62,61->63Q29
    wk1 += wk3 >> 14;                             // Q29 >> 14 -> Q15
    wk2 = ((int64_t)ik->b12 * (int64_t)tx);       // 29Q53+16-1=45 (45Q53)
    wk2 = (wk2 * (int64_t)tx) >> 22;              // 45Q53+16-1=61 (39Q31)
    wk2 = (wk2 * (int64_t)dp) >> 1;               // 39Q31+24-1=62 (61Q30)
    wk3 = wk2;                                    // 61Q30
    wk2 = ((int64_t)ik->b21 * (int64_t)tx) >> 6;  // 29Q60+16-1=45 (39Q54)
    wk2 = (wk2 * (int64_t)dp) >> 23;              // 39Q54+24-1=62 (39Q31)
    wk2 = (wk2 * (int64_t)dp) >> 1;               // 39Q31+24-1=62 (61Q20)
    wk3 += wk2;                                   // 61,61->62Q30
    wk2 = ((int64_t)ik->bp3 * (int64_t)dp) >> 12; // 28Q65+24-1=51 (39Q53)
    wk2 = (wk2 * (int64_t)dp) >> 23;              // 39Q53+24-1=62 (39Q30)
    wk2 = (wk2 * (int64_t)dp);                    // 39Q30+24-1=62 (62Q30)
    wk3 += wk2;                                   // 62,62->63Q30
    wk1 += wk3 >> 15;                             // Q30 >> 15 = Q15
    wk1 /= 32767L;
    wk1 >>= 11;     // Q15 >> 7 = Q4
    wk1 += ik->b00; // Q4 + 20Q4
    // wk1 >>= 4; // 28Q4 -> 24Q0
    ret = (int32_t)wk1;
    return ret;
}

void qmp6988_setpPowermode(qmp6988_sensor_t *dev, uint8_t mode)
{
    uint8_t data;

    qmp6988_read_data(dev, QMP6988_CTRLMEAS_REG, &data, 1);
    data &= 0xfc;
    data |= mode;

    qmp6988_write_reg(dev, QMP6988_CTRLMEAS_REG, data);
    k_msleep(20);
}

void qmp6988_setFilter(qmp6988_sensor_t *dev, uint8_t filter)
{
    uint8_t data;

    data = (filter & 0x03);
    qmp6988_write_reg(dev, QMP6988_CONFIG_REG, data);
    k_msleep(20);
}

void qmp6988_setOversamplingP(qmp6988_sensor_t *dev, uint8_t oversampling_p)
{
    uint8_t data;

    qmp6988_read_data(dev, QMP6988_CTRLMEAS_REG, &data, 1);
    data &= 0xe3;
    data |= (oversampling_p << 2);
    qmp6988_write_reg(dev, QMP6988_CTRLMEAS_REG, data);
    k_msleep(20);
}

void qmp6988_setOversamplingT(qmp6988_sensor_t *dev, uint8_t oversampling_t)
{
    uint8_t data;

    qmp6988_read_data(dev, QMP6988_CTRLMEAS_REG, &data, 1);
    data &= 0x1f;
    data |= (oversampling_t << 5);
    qmp6988_write_reg(dev, QMP6988_CTRLMEAS_REG, data);
    k_msleep(20);
}

static bool qmp6988_read_data(qmp6988_sensor_t *dev, uint8_t reg_addr, uint8_t *data, uint32_t len)
{
    if (!dev)
        return false;

    int err = i2c_write_read(dev->bus, dev->addr, &reg_addr, 1, data, len);
    if (err) {
        return false;
    }

    return true;
}

static bool qmp6988_write_reg(qmp6988_sensor_t *dev, uint8_t reg_addr, uint8_t data)
{
    if (!dev)
        return false;

    int err = i2c_reg_write_byte(dev->bus, dev->addr, reg_addr, data);
    if (err) {
        return false;
    }

    return true;
}
```

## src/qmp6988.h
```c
#ifndef __QMP6988_H__
#define __QMP6988_H__

#include <stdbool.h>
#include <stdint.h>

#include <drivers/i2c.h>

#define QMP6988_SLAVE_ADDRESS_L (0x70)
#define QMP6988_SLAVE_ADDRESS_H (0x56)

#define QMP6988_CHIP_ID 0x5C

#define QMP6988_CHIP_ID_REG     0xD1
#define QMP6988_RESET_REG       0xE0 /* Device reset register */
#define QMP6988_DEVICE_STAT_REG 0xF3 /* Device state register */
#define QMP6988_CTRLMEAS_REG    0xF4 /* Measurement Condition Control Register */
/* data */
#define QMP6988_PRESSURE_MSB_REG    0xF7 /* Pressure MSB Register */
#define QMP6988_TEMPERATURE_MSB_REG 0xFA /* Temperature MSB Reg */

/* compensation calculation */
#define QMP6988_CALIBRATION_DATA_START  0xA0 /* QMP6988 compensation coefficients */
#define QMP6988_CALIBRATION_DATA_LENGTH 25

/* power mode */
#define QMP6988_SLEEP_MODE  0x00
#define QMP6988_FORCED_MODE 0x01
#define QMP6988_NORMAL_MODE 0x03

#define QMP6988_CTRLMEAS_REG_MODE__POS 0
#define QMP6988_CTRLMEAS_REG_MODE__MSK 0x03
#define QMP6988_CTRLMEAS_REG_MODE__LEN 2

/* oversampling */
#define QMP6988_OVERSAMPLING_SKIPPED 0x00
#define QMP6988_OVERSAMPLING_1X      0x01
#define QMP6988_OVERSAMPLING_2X      0x02
#define QMP6988_OVERSAMPLING_4X      0x03
#define QMP6988_OVERSAMPLING_8X      0x04
#define QMP6988_OVERSAMPLING_16X     0x05
#define QMP6988_OVERSAMPLING_32X     0x06
#define QMP6988_OVERSAMPLING_64X     0x07

#define QMP6988_CTRLMEAS_REG_OSRST__POS 5
#define QMP6988_CTRLMEAS_REG_OSRST__MSK 0xE0
#define QMP6988_CTRLMEAS_REG_OSRST__LEN 3

#define QMP6988_CTRLMEAS_REG_OSRSP__POS 2
#define QMP6988_CTRLMEAS_REG_OSRSP__MSK 0x1C
#define QMP6988_CTRLMEAS_REG_OSRSP__LEN 3

/* filter */
#define QMP6988_FILTERCOEFF_OFF 0x00
#define QMP6988_FILTERCOEFF_2   0x01
#define QMP6988_FILTERCOEFF_4   0x02
#define QMP6988_FILTERCOEFF_8   0x03
#define QMP6988_FILTERCOEFF_16  0x04
#define QMP6988_FILTERCOEFF_32  0x05

#define QMP6988_CONFIG_REG             0xF1 /*IIR filter co-efficient setting Register*/
#define QMP6988_CONFIG_REG_FILTER__POS 0
#define QMP6988_CONFIG_REG_FILTER__MSK 0x07
#define QMP6988_CONFIG_REG_FILTER__LEN 3

#define SUBTRACTOR 8388608

typedef struct _qmp6988_cali_data {
    int32_t COE_a0;
    int16_t COE_a1;
    int16_t COE_a2;
    int32_t COE_b00;
    int16_t COE_bt1;
    int16_t COE_bt2;
    int16_t COE_bp1;
    int16_t COE_b11;
    int16_t COE_bp2;
    int16_t COE_b12;
    int16_t COE_b21;
    int16_t COE_bp3;
} qmp6988_cali_data_t;

typedef struct _qmp6988_fk_data {
    float a0, b00;
    float a1, a2, bt1, bt2, bp1, b11, bp2, b12, b21, bp3;
} qmp6988_fk_data_t;

typedef struct _qmp6988_ik_data {
    int32_t a0, b00;
    int32_t a1, a2;
    int64_t bt1, bt2, bp1, b11, bp2, b12, b21, bp3;
} qmp6988_ik_data_t;

typedef struct {
    const struct device *bus;
    uint16_t             addr;

    qmp6988_cali_data_t cali;
    qmp6988_fk_data_t   fk;
    qmp6988_ik_data_t   ik;

    float temperature;
    float pressure;
} qmp6988_sensor_t;

qmp6988_sensor_t *qmp6988_init_sensor(const struct device *i2c_dev, uint8_t addr);
bool              qmp6988_calcPressure(qmp6988_sensor_t *dev, float *pressure, float *temperature);
void              qmp6988_setpPowermode(qmp6988_sensor_t *dev, uint8_t mode);
void              qmp6988_setFilter(qmp6988_sensor_t *dev, uint8_t filter);
void              qmp6988_setOversamplingP(qmp6988_sensor_t *dev, uint8_t oversampling_p);
void              qmp6988_setOversamplingT(qmp6988_sensor_t *dev, uint8_t oversampling_t);

#endif
```

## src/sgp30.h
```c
/*
  This is a library written for the SPG30
  By Ciara Jekel @ SparkFun Electronics, June 18th, 2018


  https://github.com/sparkfun/SparkFun_SGP30_Arduino_Library

  Development environment specifics:
  Arduino IDE 1.8.5

  SparkFun labored with love to create this code. Feel like supporting open
  source hardware? Buy a board from SparkFun!
  https://www.sparkfun.com/products/14813


  CRC lookup table from Bastian Molkenthin  http://www.sunshine2k.de/coding/javascript/crc/crc_js.html

  Copyright (c) 2015 Bastian Molkenthin

  Permission is hereby granted, free of charge, to any person obtaining a copy
  of this software and associated documentation files (the "Software"), to deal
  in the Software without restriction, including without limitation the rights
  to use, copy, modify, merge, publish, distribute, sublicense, and/or sell
  copies of the Software, and to permit persons to whom the Software is
  furnished to do so, subject to the following conditions:

  The above copyright notice and this permission notice shall be included in
  all copies or substantial portions of the Software.

  THE SOFTWARE IS PROVIDED "AS IS", WITHOUT WARRANTY OF ANY KIND, EXPRESS OR
  IMPLIED, INCLUDING BUT NOT LIMITED TO THE WARRANTIES OF MERCHANTABILITY,
  FITNESS FOR A PARTICULAR PURPOSE AND NONINFRINGEMENT. IN NO EVENT SHALL THE
  AUTHORS OR COPYRIGHT HOLDERS BE LIABLE FOR ANY CLAIM, DAMAGES OR OTHER
  LIABILITY, WHETHER IN AN ACTION OF CONTRACT, TORT OR OTHERWISE, ARISING FROM,
  OUT OF OR IN CONNECTION WITH THE SOFTWARE OR THE USE OR OTHER DEALINGS IN
  THE SOFTWARE.
*/

#ifndef __SGP30_H__
#define __SGP30_H__

#include <drivers/i2c.h>
#include <stdbool.h>
#include <stdint.h>

#define SGP30_I2C_DEFAULT_ADDRESS    0x58
#define INIT_AIR_QUALITY_DURATION_MS 1000

typedef enum {
    SGP30_SUCCESS = 0,
    SGP30_ERR_BAD_CRC,
    SGP30_ERR_I2C_TIMEOUT,
    SGP30_SELF_TEST_FAIL
} SGP30ERR;

typedef struct {
    const struct device *bus;
    uint16_t             addr;

    uint16_t CO2;
    uint16_t TVOC;
    uint16_t baselineCO2;
    uint16_t baselineTVOC;
    uint16_t featureSetVersion;
    uint16_t H2;
    uint16_t ethanol;
    uint64_t serialID;
} sgp30_sensor_t;

// Start I2C communication using specified port
sgp30_sensor_t *sgp30_init_sensor(const struct device *i2c_dev, uint8_t addr);

// Initializes sensor for air quality readings
void sgp30_initAirQuality(sgp30_sensor_t *dev);

// Measure air quality
// Call in regular intervals of 1 second to maintain synamic baseline calculations
// CO2 returned in ppm, Total Volatile Organic Compounds (TVOC) returned in ppb
// Will give fixed values of CO2=400 and TVOC=0 for first 15 seconds after init
// returns false if CRC8 check failed and true if successful
bool sgp30_measureAirQuality(sgp30_sensor_t *dev);

// Returns the current calculated baseline from
// the sensor's dynamic baseline calculations
// Save baseline periodically to non volatile memory
//(like EEPROM) to restore after new power up or
// after soft reset using setBaseline();
// returns false if CRC8 check failed and true if successful
SGP30ERR sgp30_getBaseline(sgp30_sensor_t *dev);

// Updates the baseline to a previous baseline
// Should only use with previously retrieved baselines
// to maintain accuracy
void sgp30_setBaseline(sgp30_sensor_t *dev, uint16_t baselineCO2, uint16_t baselineTVOC);

// Set humidity
// humidity value is a fixed point 8.8 bit number
// Value should be absolute humidity from humidity sensor
// default value 0x0F80 = 15.5g/m^3
// minimum value 0x0001 = 1/256g/m^3
// maximum value 0xFFFF = 255+255/256 g/m^3
// sending 0x0000 resets to default and turns off humidity compensation
void sgp30_setHumidity(sgp30_sensor_t *dev, uint16_t humidity);

// Set humidity and temperature to sensor as Compensation values
// Convert relative humidity to absolute humidity
// Temperature is needed to calc absolute humidity
void sgp30_setCompensation(sgp30_sensor_t *dev, float humidity, float temperature);

// gives feature set version number (see data sheet)
// returns false if CRC8 check failed and true if successful
SGP30ERR sgp30_getFeatureSetVersion(sgp30_sensor_t *dev);

// Intended for part verification and testing
// these raw signals are used as inputs to the onchip calibrations and algorithms
SGP30ERR sgp30_measureRawSignals(sgp30_sensor_t *dev);

// Soft reset - not device specific
// will reset all devices that support general call mode
void sgp30_generalCallReset(sgp30_sensor_t *dev);

// readout of serial ID register can identify chip and verify sensor presence
// returns false if CRC8 check failed and true if successful
SGP30ERR sgp30_getSerialID(sgp30_sensor_t *dev, int64_t *serialID);

// Sensor runs on chip self test
// returns true if successful
SGP30ERR sgp30_measureTest(sgp30_sensor_t *dev);

double   RHtoAbsolute(float relHumidity, float tempC);
uint16_t doubleToFixedPoint(double number);

#ifdef SGP30_LOOKUP_TABLE
// lookup table for CRC8  http://www.sunshine2k.de/coding/javascript/crc/crc_js.html
const uint8_t _CRC8LookupTable[16][16] = {
    {0x00, 0x31, 0x62, 0x53, 0xC4, 0xF5, 0xA6, 0x97, 0xB9, 0x88, 0xDB, 0xEA, 0x7D, 0x4C, 0x1F, 0x2E},
    {0x43, 0x72, 0x21, 0x10, 0x87, 0xB6, 0xE5, 0xD4, 0xFA, 0xCB, 0x98, 0xA9, 0x3E, 0x0F, 0x5C, 0x6D},
    {0x86, 0xB7, 0xE4, 0xD5, 0x42, 0x73, 0x20, 0x11, 0x3F, 0x0E, 0x5D, 0x6C, 0xFB, 0xCA, 0x99, 0xA8},
    {0xC5, 0xF4, 0xA7, 0x96, 0x01, 0x30, 0x63, 0x52, 0x7C, 0x4D, 0x1E, 0x2F, 0xB8, 0x89, 0xDA, 0xEB},
    {0x3D, 0x0C, 0x5F, 0x6E, 0xF9, 0xC8, 0x9B, 0xAA, 0x84, 0xB5, 0xE6, 0xD7, 0x40, 0x71, 0x22, 0x13},
    {0x7E, 0x4F, 0x1C, 0x2D, 0xBA, 0x8B, 0xD8, 0xE9, 0xC7, 0xF6, 0xA5, 0x94, 0x03, 0x32, 0x61, 0x50},
    {0xBB, 0x8A, 0xD9, 0xE8, 0x7F, 0x4E, 0x1D, 0x2C, 0x02, 0x33, 0x60, 0x51, 0xC6, 0xF7, 0xA4, 0x95},
    {0xF8, 0xC9, 0x9A, 0xAB, 0x3C, 0x0D, 0x5E, 0x6F, 0x41, 0x70, 0x23, 0x12, 0x85, 0xB4, 0xE7, 0xD6},
    {0x7A, 0x4B, 0x18, 0x29, 0xBE, 0x8F, 0xDC, 0xED, 0xC3, 0xF2, 0xA1, 0x90, 0x07, 0x36, 0x65, 0x54},
    {0x39, 0x08, 0x5B, 0x6A, 0xFD, 0xCC, 0x9F, 0xAE, 0x80, 0xB1, 0xE2, 0xD3, 0x44, 0x75, 0x26, 0x17},
    {0xFC, 0xCD, 0x9E, 0xAF, 0x38, 0x09, 0x5A, 0x6B, 0x45, 0x74, 0x27, 0x16, 0x81, 0xB0, 0xE3, 0xD2},
    {0xBF, 0x8E, 0xDD, 0xEC, 0x7B, 0x4A, 0x19, 0x28, 0x06, 0x37, 0x64, 0x55, 0xC2, 0xF3, 0xA0, 0x91},
    {0x47, 0x76, 0x25, 0x14, 0x83, 0xB2, 0xE1, 0xD0, 0xFE, 0xCF, 0x9C, 0xAD, 0x3A, 0x0B, 0x58, 0x69},
    {0x04, 0x35, 0x66, 0x57, 0xC0, 0xF1, 0xA2, 0x93, 0xBD, 0x8C, 0xDF, 0xEE, 0x79, 0x48, 0x1B, 0x2A},
    {0xC1, 0xF0, 0xA3, 0x92, 0x05, 0x34, 0x67, 0x56, 0x78, 0x49, 0x1A, 0x2B, 0xBC, 0x8D, 0xDE, 0xEF},
    {0x82, 0xB3, 0xE0, 0xD1, 0x46, 0x77, 0x24, 0x15, 0x3B, 0x0A, 0x59, 0x68, 0xFF, 0xCE, 0x9D, 0xAC}};
#endif

#endif
```
